# MM32F013x register map
File version: 1.01
CPU: CM0 r0p0, little endian, no MPU, no FPU, 2 interrupt priority bits
Registers are 32-bit, read-write, reset 0x0 unless marked. A register's access mark holds for its fields unless they carry their own. Offsets are from the block's base; [hi:lo] are bit positions; {n}, {i} and the like mark numbered series.

## TIM1 — Advanced timer
Base 0x40012C00
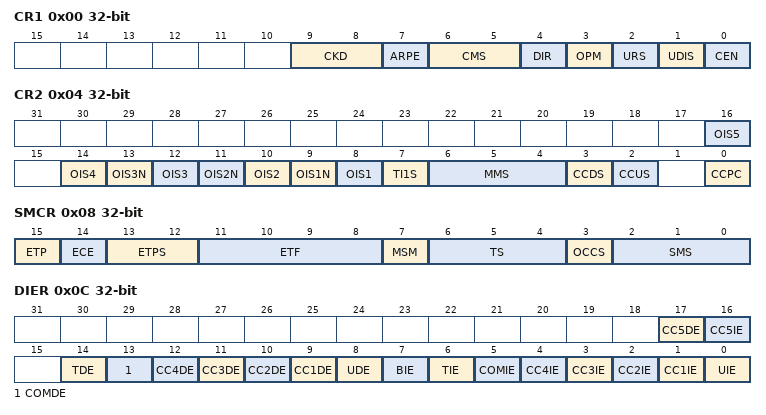
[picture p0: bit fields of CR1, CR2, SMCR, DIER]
0x00 CR1 — control register 1
  [9:8] CKD — Clock division
  [7] ARPE — Auto-reload preload enable
  [6:5] CMS — Center-aligned mode selection
  [4] DIR — Direction
  [3] OPM — One pulse mode
  [2] URS — Update request source
  [1] UDIS — Update disable
  [0] CEN — Counter enable
0x04 CR2 — control register 2
  [2n+6] OIS{n} (n=2..5)
  [13] OIS3N
  [11] OIS2N
  [9] OIS1N — Output Idle state 1
  [8] OIS1 — Output Idle state 1
  [7] TI1S — TI1 selection
  [6:4] MMS — Master mode selection
  [3] CCDS — Capture/compare DMA selection
  [2] CCUS — Capture/compare control update selection
  [0] CCPC — Capture/compare preloaded control
0x08 SMCR — slave mode control register 1
  [15] ETP — External trigger polarity
  [14] ECE — External clock enable
  [13:12] ETPS — External trigger prescaler
  [11:8] ETF — External trigger filter
  [7] MSM — Master/slave mode
  [6:4] TS — Trigger selection
  [3] OCCS — Output compare clear selection
  [2:0] SMS — Slave mode selection
0x0C DIER — DMA/Interrupt enable register
  [17] CC5DE — Capture/Compare 5 DMA request enable
  [16] CC5IE — Capture/Compare 5 interrupt enable
  [14] TDE — Trigger DMA request enable
  [13] COMDE — COM DMA request enable
  [n+8] CC{n}DE (n=1..4) — Capture/Compare {n} DMA request enable
  [8] UDE — Update DMA request enable
  [7] BIE — Break interrupt enable
  [6] TIE — Trigger interrupt enable
  [5] COMIE — COM interrupt enable
  [n] CC{n}IE (n=1..4) — Capture/Compare {n} interrupt enable
  [0] UIE — Update interrupt enable
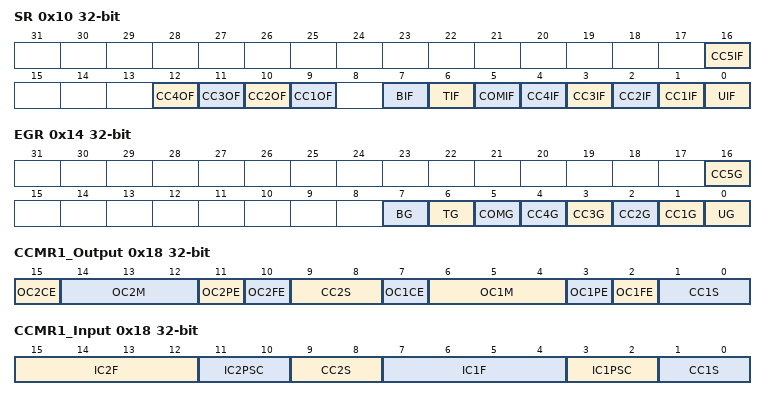
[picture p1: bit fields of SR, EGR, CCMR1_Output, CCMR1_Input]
0x10 SR — status register
  [16] CC5IF — Capture/Compare 5 interrupt flag
  [n+8] CC{n}OF (n=1..4) — Capture/Compare {n} overcapture flag
  [7] BIF — Break interrupt flag
  [6] TIF — Trigger interrupt flag
  [5] COMIF — COM interrupt flag
  [n] CC{n}IF (n=1..4) — Capture/Compare {n} interrupt flag
  [0] UIF — Update interrupt flag
0x14 EGR wo — event generation register
  [16] CC5G — Capture/Compare 5 generation
  [7] BG — Break generation
  [6] TG — Trigger generation
  [5] COMG — Capture/Compare control update generation
  [n] CC{n}G (n=1..4) — Capture/Compare {n} generation
  [0] UG — Update generation
0x18 CCMR1_Output — capture/compare mode register 1 (output mode)
  [15] OC2CE — Output compare 2 clear enable
  [14:12] OC2M — Output compare 2 mode
  [11] OC2PE — Output compare 2 preload enable
  [10] OC2FE — Output compare 4 fast enable
  [9:8] CC2S — Capure/Compare 2 selection
  [7] OC1CE — Output compare 1 clear enable
  [6:4] OC1M — Output compare 1 mode
  [3] OC1PE — Output compare 1 preload enable
  [2] OC1FE — Output compare 1 fast enable
  [1:0] CC1S — Capture/Compare 2 output enable
0x18 CCMR1_Input (alternate view of CCMR1_Output) — capture/compare mode register 1 (input mode)
  [15:12] IC2F — Input capture 2 filter
  [11:10] IC2PSC — Input capture 2 prescaler
  [9:8] CC2S — Capture/Compare 2 selection
  [7:4] IC1F — Input capture 1 filter
  [3:2] IC1PSC — Input capture 1 prescaler
  [1:0] CC1S — Capture/compare 1 selection
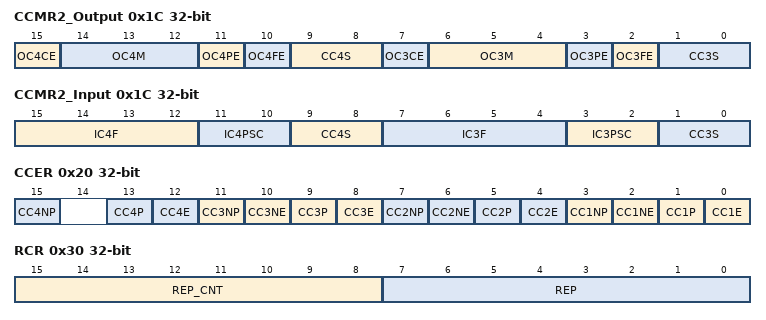
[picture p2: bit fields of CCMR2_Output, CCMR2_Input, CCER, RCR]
0x1C CCMR2_Output — capture/compare mode register 2(output mode)
  [15] OC4CE — Output compare 4 clear enable
  [14:12] OC4M — Output compare 4 mode
  [11] OC4PE — Output compare 4 preload enable
  [10] OC4FE — Output compare 4 fast enable
  [9:8] CC4S — Capture/Compare 4 selection
  [7] OC3CE — Output compare 3 clear enable
  [6:4] OC3M — Output compare 3 mode
  [3] OC3PE — Output compare 3 preload enable
  [2] OC3FE — Output compare 3 fast enable
  [1:0] CC3S — Capture/Compare 3 selection
0x1C CCMR2_Input (alternate view of CCMR2_Output) — capture/compare mode register 2 (input mode)
  [15:12] IC4F — Input capture 4 filter
  [11:10] IC4PSC — Input capture 4 prescaler
  [9:8] CC4S — Capture/Compare 4 selection
  [7:4] IC3F — Input capture 3 filter
  [3:2] IC3PSC — Input capture 3 prescaler
  [1:0] CC3S — Capture/compare 3 selection
0x20 CCER — capture/compare enable register
  [4n-1] CC{n}NP (n=1..4) — Capture/Compare {n} complementary output polarity
  [4n-3] CC{n}P (n=1..4) — Capture/Compare {n} output polarity
  [4n-4] CC{n}E (n=1..4) — Capture/Compare {n} output enable
  [10] CC3NE — Capture/Compare 3 complementary output enable
  [6] CC2NE — Capture/Compare 2 complementary output enable
  [2] CC1NE — Capture/Compare 1 complementary output enable
0x24 CNT — counter
  [15:0] CNT — Counter value
0x28 PSC — prescaler
  [15:0] PSC — Prescaler value
0x2C ARR — auto-reload register
  [15:0] ARR — Auto reload value
0x30 RCR — repetition counter register
  [15:8] REP_CNT — Repetition counter value of real-time writing
  [7:0] REP — Repetition counter value
{0x30+4i} CCR{i} (i=1..4) — capture/compare register {i}
  [15:0] CCR{i} — Capture/Compare {i} value
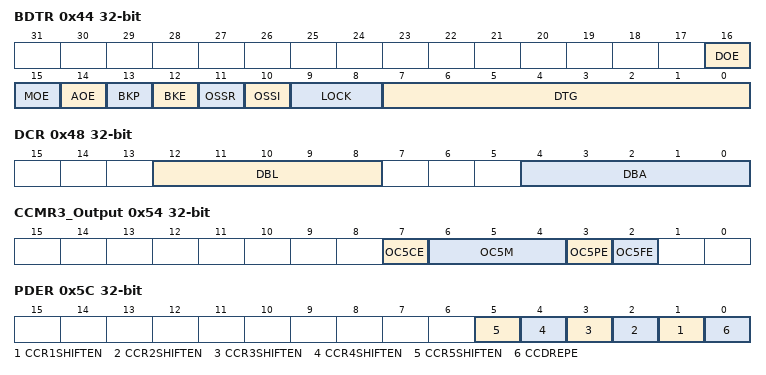
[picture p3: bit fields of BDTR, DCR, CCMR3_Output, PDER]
0x44 BDTR — break and dead-time register
  [16] DOE — Direct output enable
  [15] MOE — Main output enable
  [14] AOE — Automatic output enable
  [13] BKP — Break polarity
  [12] BKE — Break enable
  [11] OSSR — Off-state selection for Run mode
  [10] OSSI — Off-state selection for Idle mode
  [9:8] LOCK — Lock configuration
  [7:0] DTG — Dead-time generator setup
0x48 DCR wo — DMA control register
  [12:8] DBL — DMA burst length
  [4:0] DBA — DMA base address
0x4C DMAR wo — DMA address for full transfer
  [15:0] DMAB — DMA register for burst accesses
0x54 CCMR3_Output — capture/compare mode register 3 (output mode)
  [7] OC5CE — Output compare 5 clear enable
  [6:4] OC5M — Output compare 5 mode
  [3] OC5PE — Output compare 5 preload enable
  [2] OC5FE — Output compare 5 fast enable
0x58 CCR5 — capture/compare register 5
  [15:0] CCR5 — Capture/Compare 5 value
0x5C PDER — PWM/DMA repeat enable register
  [n] CCR{n}SHIFTEN (n=1..5) — CCR{n} pwm shift enable
  [0] CCDREPE — DMA request flow enable
{0x5C+4i} CCR{i}FALL (i=1..5) — pwm shift count CCR{i} register
  [15:0] CCR{i}FALL — Capture/compare value for ch{i} when counting down in PWM center-aligned mode

## TIM2 — General purpose timer
Base 0x40000000
Registers as TIM1, without RCR, BDTR, CCMR3_Output, CCR5, PDER, CCR{n}FALL (n=1..5); these are added or differ:
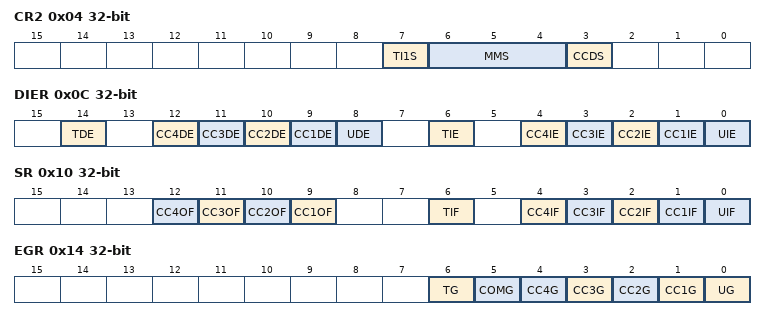
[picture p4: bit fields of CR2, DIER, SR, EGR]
0x04 CR2 — control register 2
  [7] TI1S — TI1 selection
  [6:4] MMS — Master mode selection
  [3] CCDS — Capture/Compare DMA selection
0x0C DIER — DMA/Interrupt enable register
  [14] TDE — Trigger DMA request enable
  [n+8] CC{n}DE (n=1..4) — Capture/Compare {n} DMA request enable
  [8] UDE — Update DMA request enable
  [6] TIE — Trigger interrupt enable
  [n] CC{n}IE (n=1..4) — Capture/Compare {n} interrupt enable
  [0] UIE — Update interrupt enable
0x10 SR — status register
  [n+8] CC{n}OF (n=1..4) — Capture/Compare {n} overcapture flag
  [6] TIF — Trigger interrupt flag
  [n] CC{n}IF (n=1..4) — Capture/Compare {n} interrupt flag
  [0] UIF — Update interrupt flag
0x14 EGR wo — event generation register
  [6] TG — Trigger generation
  [5] COMG — Capture/Compare control update generation
  [n] CC{n}G (n=1..4) — Capture/compare {n} generation
  [0] UG — Update generation
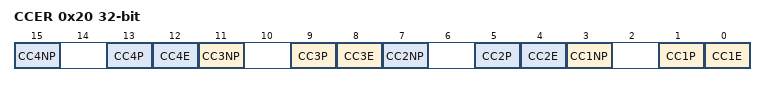
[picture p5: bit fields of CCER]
0x20 CCER — capture/compare enable register
  [4n-1] CC{n}NP (n=1..4) — Capture/Compare {n} complementary output polarity
  [4n-3] CC{n}P (n=1..4) — Capture/Compare {n} output polarity
  [4n-4] CC{n}E (n=1..4) — Capture/Compare {n} output enable
0x24 CNT — counter
  [31:0] CNT — Counter value
0x2C ARR — auto-reload register
  [31:0] ARR — Auto reload value
{0x30+4i} CCR{i} (i=1..4) — capture/compare register {i}
  [31:0] CCR{i} — Capture/Compare {i} value

## TIM3 — General purpose timer
Base 0x40000400
Registers as TIM2; these are added or differ:
0x24 CNT — counter
  [15:0] CNT — Counter value
0x2C ARR — auto-reload register
  [15:0] ARR — Auto reload value
{0x30+4i} CCR{i} (i=1..4) — capture/compare register {i}
  [15:0] CCR{i} — Capture/Compare {i} value
